# psoc6_04 register map
Vendor: Infineon Technologies; Series: PSOC6_04; File version: 1.0
CPU: CM4 r0p1, little endian, MPU, FPU, VTOR, 3 interrupt priority bits
Registers are 32-bit, read-write, reset 0x0 unless marked. A register's access mark holds for its fields unless they carry their own. Offsets are from the block's base; [hi:lo] are bit positions; {n}, {i} and the like mark numbered series; 'fields as' and 'values as' point back to an identical list; <NAME> marks a mode.

## SAR0 — SAR ADC with Sequencer
Base 0x409B0000
Same registers: SAR1 0x409C0000
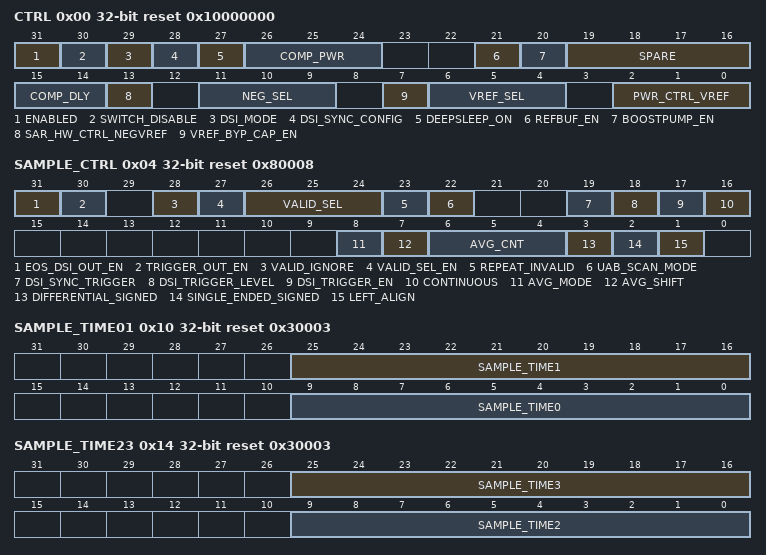
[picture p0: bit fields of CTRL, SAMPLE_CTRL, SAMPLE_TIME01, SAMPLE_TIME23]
0x00 CTRL reset 0x10000000 — Analog control register.
  [31] ENABLED — - 0: SAR disabled (put analog in power down and stop clocks), also can clear FW_TRIGGER on write. - 1: SAR IP enabled.
  [30] SWITCH_DISABLE — Disable SAR sequencer from enabling routing switches - 0: Normal mode, SAR sequencer changes switches according to pin address in channel configurations - 1: Switches disabled, SAR sequencer does not enable any switches. Other methods such as firmware control can be used to set the switches to route the signal to be converted through the SARMUX
  [29] DSI_MODE — SAR sequencer takes configuration from DSI signals (note this also has the same effect as SWITCH_DISABLE==1) - 0: Normal mode, SAR sequencer operates according to CHAN_EN enables and CHAN_CONFIG channel configurations - 1: CHAN_EN and channel configurations in CHAN_CONFIG are ignored
  [28] DSI_SYNC_CONFIG
  [27] DEEPSLEEP_ON — - 0: SARMUX disabled during System Deep Sleep power mode - 1: SARMUX remains enabled during System Deep Sleep power mode (if ENABLED=1)
  [26:24] COMP_PWR — Comparator power mode.
    0=P100 (Power = 100 percent, Use this for SAR Clock Frequency greater than 18MHz); 1=P80 (N/A); 2=P60 (Power = 60 percent, Use this for SAR Clock Frequency greater than 1.8MHz up to 18MHz.); 3=P50 (N/A); 4=P40 (N/A); 5=P30 (N/A); 6=P20 (Power = 20 percent, Use this for SAR Clock Frequency less than or equal to 1.8MHz); 7=P10 (N/A)
  [21] REFBUF_EN
  [20] BOOSTPUMP_EN
  [19:16] SPARE
  [15:14] COMP_DLY
    0=D2P5 (2.5ns delay, use this for 2.5Msps); 1=D4 (4.0ns delay, use this for 2.0Msps); 2=D10 (10ns delay, use this for 1.5Msps); 3=D12 (12ns delay, use this for 1.0Msps or less)
  [13] SAR_HW_CTRL_NEGVREF
  [11:9] NEG_SEL
    0=VSSA_KELVIN (NEG input of SARADC is connected to 'vssa_kelvin', gives more precision around zero. Note this opens both SARADC internal switches, therefore use this value to insert a break-before-make cycle on those switches when SWITCH_DISABLE is high.); 1=ART_VSSA (NEG input of SARADC is connected to VSSA in AROUTE close to the SARADC); 2=P1 (NEG input of SARADC is connected to P1 pin of SARMUX); 3=P3 (NEG input of SARADC is connected to P3 pin of SARMUX); 4=P5 (NEG input of SARADC is connected to P5 pin of SARMUX); 5=P7 (NEG input of SARADC is connected to P7 pin of SARMUX); 6=ACORE (NEG input of SARADC is connected to an ACORE in AROUTE); 7=VREF (NEG input of SARADC is shorted with VREF input of SARADC.)
  [7] VREF_BYP_CAP_EN — VREF bypass cap enable when VREF buffer is on
  [6:4] VREF_SEL
    0=VREF0 (VREF0 from PRB (VREF buffer on)); 1=VREF1 (VREF1 from PRB (VREF buffer on)); 2=VREF2 (VREF2 from PRB (VREF buffer on)); 3=VREF_AROUTE (VREF from AROUTE (VREF buffer on)); 4=VBGR (1.024V from BandGap (VREF buffer on)); 5=VREF_EXT (External precision Vref direct from a pin (low impedance path).); 6=VDDA_DIV_2 (Vdda/2 (VREF buffer on)); 7=VDDA
  [2:0] PWR_CTRL_VREF — VREF buffer low power mode.
    0=PWR_100 (full power (100 percent) (default), bypass cap, max clk_sar is 18MHz.); 1=PWR_80 (80 percent power); 2=PWR_60 (60 percent power); 3=PWR_50 (50 percent power); 4=PWR_40 (40 percent power); 5=PWR_30 (30 percent power); 6=PWR_20 (20 percent power); 7=PWR_10 (10 percent power)
0x04 SAMPLE_CTRL reset 0x80008 — Sample control register.
  [31] EOS_DSI_OUT_EN — Enable to output EOS_INTR. When enabled each time EOS_INTR is set by the hardware also a trigger pulse is send on the tr_sar_out signal.
  [30] TRIGGER_OUT_EN
  [28] VALID_IGNORE
  [27] VALID_SEL_EN
  [26:24] VALID_SEL
  [23] REPEAT_INVALID
  [22] UAB_SCAN_MODE
    0=UNSCHEDULED (Unscheduled UABs: one or more of the UABs scanned by the SAR is not scheduled, for each channel that scans a UAB the SAR will wait for a positive edge on the trigger output of that UAB. Caveat: in this mode the length of SAR scan can be variable.); 1=SCHEDULED (Scheduled UABs: All UABs scanned by the SAR are assumed to be properly scheduled, i.e. their output is assumed to be valid when sampled by the SAR and the SAR does not wait. In this mode the length of the SAR scan is constant. This mode requires that the SAR scans strictly periodically, i.e. the SAR has to either run continuously or has to be triggered by a periodic hardware trigger (TCPWM or UDB timer). It also requires that the end of the UAB valid phase is precisely aligned with the end of the SAR sample period (using UAB.STARTUP_DELAY). Normally this scheduling is done by Creator.)
  [19] DSI_SYNC_TRIGGER
  [18] DSI_TRIGGER_LEVEL
  [17] DSI_TRIGGER_EN — - 0: firmware trigger only: disable hardware trigger tr_sar_in. - 1: enable hardware trigger tr_sar_in (e.g. from TCPWM, GPIO etc)
  [16] CONTINUOUS
  [8] AVG_MODE — Averaging mode
    0=ACCUNDUMP (Accumulate and Dump (1st order accumulate and dump filter): a channel will be sampled back to back and averaged); 1=INTERLEAVED (Interleaved: Each scan (trigger) one sample is taken per channel and averaged over several scans. Interleaved averaging cannot be set by SAR_CLOCK_SEL.CLOCK_SEL =1.)
  [7] AVG_SHIFT
  [6:4] AVG_CNT
  [3] DIFFERENTIAL_SIGNED
    0=UNSIGNED (result data is unsigned (zero extended if needed)); 1=SIGNED (Default: result data is signed (sign extended if needed))
  [2] SINGLE_ENDED_SIGNED
    0=UNSIGNED (Default: result data is unsigned (zero extended if needed)); 1=SIGNED (result data is signed (sign extended if needed))
  [1] LEFT_ALIGN
0x10 SAMPLE_TIME01 reset 0x30003 — Sample time specification ST0 and ST1
  [25:16] SAMPLE_TIME1
  [9:0] SAMPLE_TIME0 — Sample time0 (aperture) in ADC clock cycles. Note that actual sample time is one clock less than specified here. The minimum sample time is 167ns, which is 3.0 cycles (4 in this field) with an 18MHz clock. Minimum legal value in this register is 2.
0x14 SAMPLE_TIME23 reset 0x30003 — Sample time specification ST2 and ST3
  [25:16] SAMPLE_TIME3, [9:0] SAMPLE_TIME2
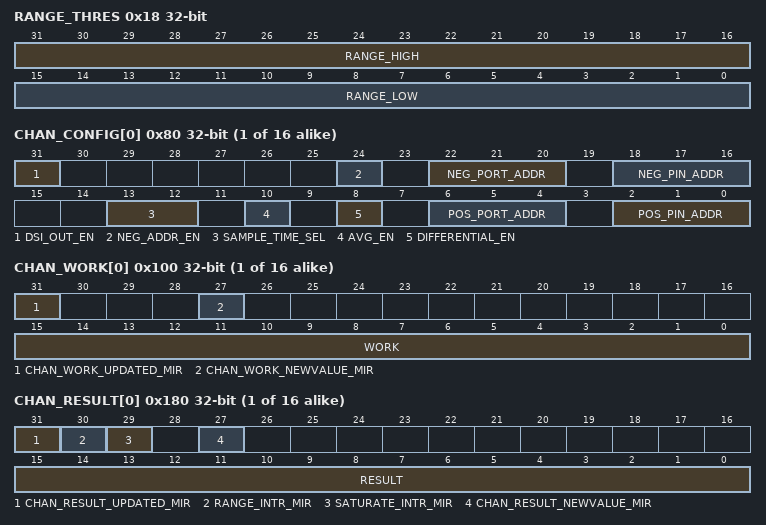
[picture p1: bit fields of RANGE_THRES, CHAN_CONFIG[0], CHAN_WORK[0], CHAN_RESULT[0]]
0x18 RANGE_THRES — Global range detect threshold register.
  [31:16] RANGE_HIGH — High threshold for range detect.
  [15:0] RANGE_LOW — Low threshold for range detect.
0x1C RANGE_COND — Global range detect mode register.
  [31:30] RANGE_COND — Range condition select.
    0=BELOW (result < RANGE_LOW); 1=INSIDE (RANGE_LOW <= result < RANGE_HIGH); 2=ABOVE (RANGE_HIGH <= result); 3=OUTSIDE (result < RANGE_LOW || RANGE_HIGH <= result)
0x20 CHAN_EN — Enable bits for the channels
  [15:0] CHAN_EN — Channel enable. - 0: the corresponding channel is disabled. - 1: the corresponding channel is enabled, it will be included in the next scan.
0x24 START_CTRL — Start control register (firmware trigger).
  [0] FW_TRIGGER — When firmware writes a 1 here it will trigger the next scan of enabled channels, hardware clears this bit when the scan started with this trigger is completed. If scanning continuously the trigger is ignored and hardware clears this bit after the next scan is done. This bit is also cleared when the SAR is disabled. This field cannot be set when SAR_CLOCK_SEL.CLOCK_SEL =1.
{0x80+4i} CHAN_CONFIG[{i}] (i=0..15) — Channel configuration register.
  [31] DSI_OUT_EN
  [24] NEG_ADDR_EN
  [22:20] NEG_PORT_ADDR
    0=SARMUX (SARMUX pins.); 5=AROUTE_VIRT2 (AROUTE virtual port2 (VPORT2)); 6=AROUTE_VIRT1 (AROUTE virtual port1 (VPORT1)); 7=SARMUX_VIRT (SARMUX virtual port (VPORT0))
  [18:16] NEG_PIN_ADDR — Address of the neg pin to be sampled by this channel. When NEG_PORT_ADDR = SARMUX, NEG_PIN_ADDR selects the pin of the SARMUX port.
  [13:12] SAMPLE_TIME_SEL
  [10] AVG_EN
  [8] DIFFERENTIAL_EN
  [6:4] POS_PORT_ADDR
    0=SARMUX (SARMUX pins.); {v}=CTB{v-1} (v=1..4); 5=AROUTE_VIRT2 (AROUTE virtual port2 (VPORT2)); 6=AROUTE_VIRT1 (AROUTE virtual port1 (VPORT1)); 7=SARMUX_VIRT (SARMUX virtual port (VPORT0))
  [2:0] POS_PIN_ADDR — Address of the pin to be sampled by this channel (connected to Vplus). When POS_PORT_ADDR = SARMUX, POS_PIN_ADDR selects the pin of the SARMUX port. When POS_PORT_ADDR is set to one of the CTBs, POS_PIN_ADDR selects particular opamp output. When POS_PORT_ADDR is set to VPORT0, POS_PIN_ADDR = 0, selects temperature sensor output, POS_PIN_ADDR = 1 selects AMUXBUS-A and POS_PIN_ADDR = 2 selects AMUXBUS-B.
{0x100+4i} CHAN_WORK[{i}] (i=0..15) ro (reset mask 0x88000000) — Channel working data register
  [31] CHAN_WORK_UPDATED_MIR — mirror bit of corresponding bit in SAR_CHAN_WORK_UPDATED register. This field cannot be read if SAR_CLOCK_SEL.CLOCK_SEL =1.
  [27] CHAN_WORK_NEWVALUE_MIR — mirror bit of corresponding bit in SAR_CHAN_WORK_NEWVALUE register. This field cannot be read if SAR_CLOCK_SEL.CLOCK_SEL =1.
  [15:0] WORK — SAR conversion working data of the channel. The data is written here right after sampling this channel. This field cannot be read if SAR_CLOCK_SEL.CLOCK_SEL =1.
{0x180+4i} CHAN_RESULT[{i}] (i=0..15) ro (reset mask 0xE8000000) — Channel result data register
  [31] CHAN_RESULT_UPDATED_MIR — mirror bit of corresponding bit in SAR_CHAN_RESULT_UPDATED register. This field cannot be read if SAR_CLOCK_SEL.CLOCK_SEL =1.
  [30] RANGE_INTR_MIR — mirror bit of corresponding bit in SAR_RANGE_INTR register. This field cannot be read if SAR_CLOCK_SEL.CLOCK_SEL =1.
  [29] SATURATE_INTR_MIR — mirror bit of corresponding bit in SAR_SATURATE_INTR register. This field cannot be read if SAR_CLOCK_SEL.CLOCK_SEL =1.
  [27] CHAN_RESULT_NEWVALUE_MIR — mirror bit of corresponding bit in SAR_CHAN_RESULT_NEWVALUE register. This field cannot be read if SAR_CLOCK_SEL.CLOCK_SEL =1.
  [15:0] RESULT — SAR conversion result of the channel. The data is copied here from the WORK field after all enabled channels in this scan have been sampled. This field cannot be read if SAR_CLOCK_SEL.CLOCK_SEL =1.
0x200 CHAN_WORK_UPDATED ro — Channel working data register 'updated' bits
  [15:0] CHAN_WORK_UPDATED — If set the corresponding WORK register was updated, i.e. was already sampled during the current scan and, in case of Interleaved averaging, reached the averaging count. If this bit is low then either the channel is not enabled or the averaging count is not yet reached for Interleaved averaging. This field cannot be read if SAR_CLOCK_SEL.CLOCK_SEL =1.
0x204 CHAN_RESULT_UPDATED ro — Channel result data register 'updated' bits
  [15:0] CHAN_RESULT_UPDATED — If set the corresponding RESULT register was updated, i.e. was sampled during the previous scan and, in case of Interleaved averaging, reached the averaging count. If this bit is low then either the channel is not enabled or the averaging count is not yet reached for Interleaved averaging. This field cannot be read if SAR_CLOCK_SEL.CLOCK_SEL =1.
0x208 CHAN_WORK_NEWVALUE ro — Channel working data register 'new value' bits
  [15:0] CHAN_WORK_NEWVALUE — If set the corresponding WORK data received a new value, i.e. was already sampled during the current scan and data was valid. In case of a UAB this New Value bit reflects the value of UAB.valid output, for anything else the data is always valid. In case of averaging this New Value bit is an OR of all the valid bits received by each conversion. This field cannot be read if SAR_CLOCK_SEL.CLOCK_SEL =1.
0x20C CHAN_RESULT_NEWVALUE ro — Channel result data register 'new value' bits
  [15:0] CHAN_RESULT_NEWVALUE — If set the corresponding RESULT data received a new value, i.e. was sampled during the last scan and data was valid. In case of a UAB this New Value bit reflects the value of UAB.valid output, for anything else the data is always valid. In case of averaging this New Value bit is an OR of all the valid bits received by each conversion. This field cannot be read if SAR_CLOCK_SEL.CLOCK_SEL =1.
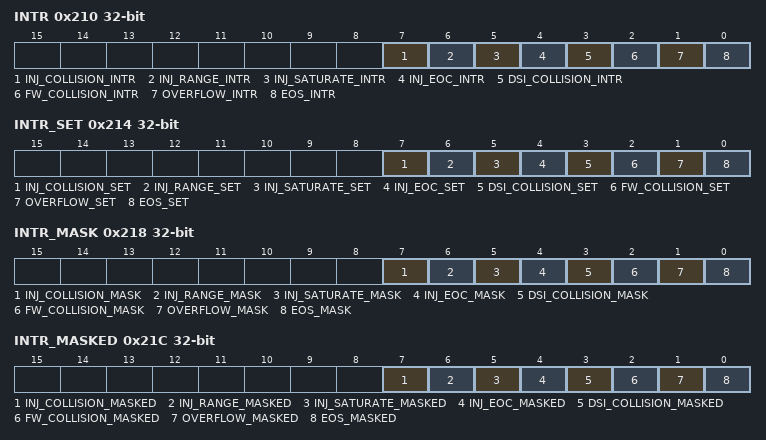
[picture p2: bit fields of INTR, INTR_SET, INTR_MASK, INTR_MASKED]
0x210 INTR — Interrupt request register.
  [7] INJ_COLLISION_INTR
  [6] INJ_RANGE_INTR
  [5] INJ_SATURATE_INTR
  [4] INJ_EOC_INTR
  [3] DSI_COLLISION_INTR — This interrupt is set when a hardware trigger signal is asserted while the SAR is BUSY. Raising this interrupt is delayed to when the scan caused by the hardware trigger has been completed, i.e. not when the preceding scan with which this trigger collided is completed. When this interrupt is set it implies that the channels were sampled later than was intended (jitter). Write with '1' to clear bit.
  [2] FW_COLLISION_INTR
  [1] OVERFLOW_INTR
  [0] EOS_INTR
0x214 INTR_SET — Interrupt set request register
  [7] INJ_COLLISION_SET, [6] INJ_RANGE_SET, [5] INJ_SATURATE_SET, [4] INJ_EOC_SET, [3] DSI_COLLISION_SET, [2] FW_COLLISION_SET, [1] OVERFLOW_SET, [0] EOS_SET
0x218 INTR_MASK — Interrupt mask register.
  [7] INJ_COLLISION_MASK, [6] INJ_RANGE_MASK, [5] INJ_SATURATE_MASK, [4] INJ_EOC_MASK, [3] DSI_COLLISION_MASK, [2] FW_COLLISION_MASK, [1] OVERFLOW_MASK, [0] EOS_MASK
0x21C INTR_MASKED ro — Interrupt masked request register
  [7] INJ_COLLISION_MASKED, [6] INJ_RANGE_MASKED, [5] INJ_SATURATE_MASKED, [4] INJ_EOC_MASKED, [3] DSI_COLLISION_MASKED, [2] FW_COLLISION_MASKED, [1] OVERFLOW_MASKED, [0] EOS_MASKED
0x220 SATURATE_INTR — Saturate interrupt request register.
  [15:0] SATURATE_INTR — Saturate Interrupt: hardware sets this interrupt for each channel if a conversion result (before averaging) of that channel is either 0x000 or 0xFFF, this is an indication that the ADC likely saturated. Write with '1' to clear bit.
0x224 SATURATE_INTR_SET — Saturate interrupt set request register
  [15:0] SATURATE_SET — Write with '1' to set corresponding bit in interrupt request register.
0x228 SATURATE_INTR_MASK — Saturate interrupt mask register.
  [15:0] SATURATE_MASK — Mask bit for corresponding bit in interrupt request register.
0x22C SATURATE_INTR_MASKED ro — Saturate interrupt masked request register
  [15:0] SATURATE_MASKED — Logical and of corresponding request and mask bits.
0x230 RANGE_INTR — Range detect interrupt request register.
  [15:0] RANGE_INTR — Range detect Interrupt: hardware sets this interrupt for each channel if the conversion result (after averaging) of that channel met the condition specified by the SAR_RANGE registers. Write with '1' to clear bit.
0x234 RANGE_INTR_SET — Range detect interrupt set request register
  [15:0] RANGE_SET — Write with '1' to set corresponding bit in interrupt request register.
0x238 RANGE_INTR_MASK — Range detect interrupt mask register.
  [15:0] RANGE_MASK — Mask bit for corresponding bit in interrupt request register.
0x23C RANGE_INTR_MASKED ro — Range interrupt masked request register
  [15:0] RANGE_MASKED — Logical and of corresponding request and mask bits.
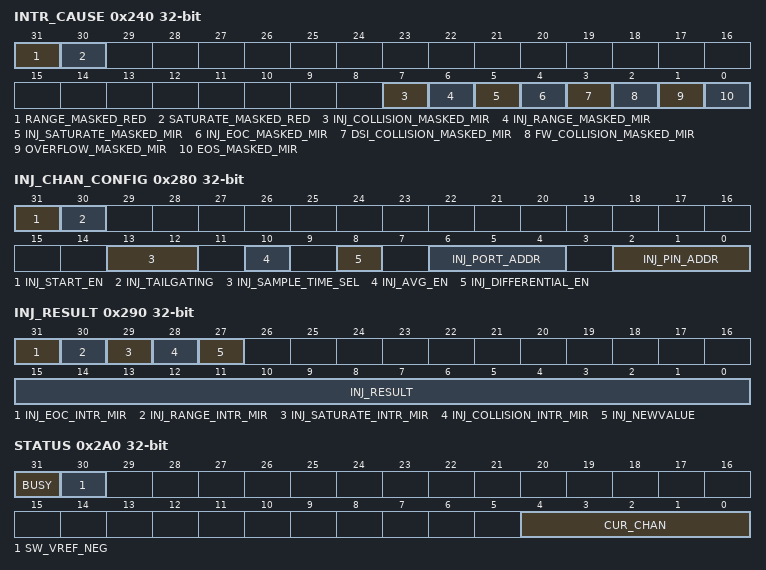
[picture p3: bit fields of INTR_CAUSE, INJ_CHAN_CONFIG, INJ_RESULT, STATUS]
0x240 INTR_CAUSE ro — Interrupt cause register
  [31] RANGE_MASKED_RED, [30] SATURATE_MASKED_RED, [7] INJ_COLLISION_MASKED_MIR, [6] INJ_RANGE_MASKED_MIR, [5] INJ_SATURATE_MASKED_MIR, [4] INJ_EOC_MASKED_MIR, [3] DSI_COLLISION_MASKED_MIR, [2] FW_COLLISION_MASKED_MIR, [1] OVERFLOW_MASKED_MIR, [0] EOS_MASKED_MIR
0x280 INJ_CHAN_CONFIG — Injection channel configuration register.
  [31] INJ_START_EN
  [30] INJ_TAILGATING
  [13:12] INJ_SAMPLE_TIME_SEL
  [10] INJ_AVG_EN
  [8] INJ_DIFFERENTIAL_EN
  [6:4] INJ_PORT_ADDR
    0=SARMUX (SARMUX pins.); {v}=CTB{v-1} (v=1..4); 6=AROUTE_VIRT (AROUTE virtual port); 7=SARMUX_VIRT (SARMUX virtual port)
  [2:0] INJ_PIN_ADDR
0x290 INJ_RESULT ro (reset mask 0xF8000000) — Injection channel result register
  [31] INJ_EOC_INTR_MIR — mirror bit of corresponding bit in SAR_INTR register. This field cannot be read if SAR_CLOCK_SEL.CLOCK_SEL =1.
  [30] INJ_RANGE_INTR_MIR — mirror bit of corresponding bit in SAR_INTR register. This field cannot be read if SAR_CLOCK_SEL.CLOCK_SEL =1.
  [29] INJ_SATURATE_INTR_MIR — mirror bit of corresponding bit in SAR_INTR register. This field cannot be read if SAR_CLOCK_SEL.CLOCK_SEL =1.
  [28] INJ_COLLISION_INTR_MIR — mirror bit of corresponding bit in SAR_INTR register. This field cannot be read if SAR_CLOCK_SEL.CLOCK_SEL =1.
  [27] INJ_NEWVALUE — The data in this register received a new value (only relevant for UAB, this bit shows the value of the UAB valid bit). This field cannot be read if SAR_CLOCK_SEL.CLOCK_SEL =1.
  [15:0] INJ_RESULT — SAR conversion result of the channel. This field cannot be read if SAR_CLOCK_SEL.CLOCK_SEL =1.
0x2A0 STATUS ro — Current status of internal SAR registers (mostly for debug)
  [31] BUSY — If high then the SAR is busy with a conversion. This bit is always high when CONTINUOUS is set. Firmware should wait for this bit to be low before putting the SAR in power down.
  [30] SW_VREF_NEG — the current switch status, including DSI and sequencer controls, of the switch in the SARADC that shorts NEG with VREF input (see NEG_SEL). This field cannot be read if SAR_CLOCK_SEL.CLOCK_SEL =1.
  [4:0] CUR_CHAN — current channel being sampled (channel 16 indicates the injection channel), only valid if BUSY. This field cannot be read if SAR_CLOCK_SEL.CLOCK_SEL =1.
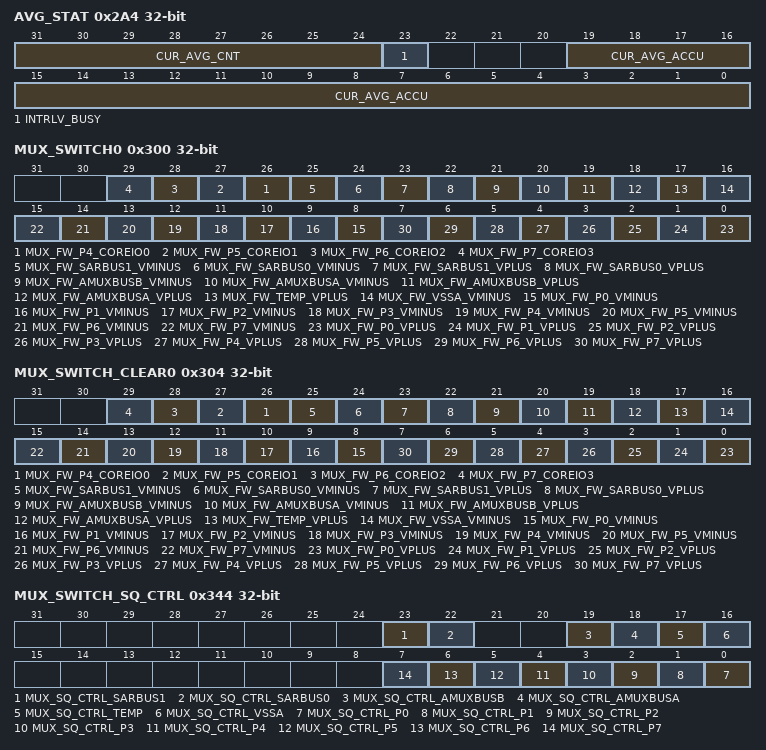
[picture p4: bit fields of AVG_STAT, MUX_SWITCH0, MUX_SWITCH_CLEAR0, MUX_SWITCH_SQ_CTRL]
0x2A4 AVG_STAT ro — Current averaging status (for debug)
  [31:24] CUR_AVG_CNT — the current value of the averaging counter. Note that the value shown is updated after the sampling time and therefore runs ahead of the accumulator update. This field cannot be read if SAR_CLOCK_SEL.CLOCK_SEL =1.
  [23] INTRLV_BUSY — If high then the SAR is in the middle of Interleaved averaging spanning several scans. While this bit is high the Firmware should not make any changes to the configuration registers otherwise some results may be incorrect. Note that the CUR_AVG_CNT status register below gives an indication how many more scans need to be done to complete the Interleaved averaging. This bit can be cleared by changing the averaging mode to ACCUNDUMP or by disabling the SAR.
  [19:0] CUR_AVG_ACCU — the current value of the averaging accumulator. This field cannot be read if SAR_CLOCK_SEL.CLOCK_SEL =1.
0x300 MUX_SWITCH0 — SARMUX Firmware switch controls
  [n+22] MUX_FW_P{n}_COREIO{n-4} (n=4..7), [25] MUX_FW_SARBUS1_VMINUS, [24] MUX_FW_SARBUS0_VMINUS, [23] MUX_FW_SARBUS1_VPLUS, [22] MUX_FW_SARBUS0_VPLUS, [21] MUX_FW_AMUXBUSB_VMINUS, [20] MUX_FW_AMUXBUSA_VMINUS, [19] MUX_FW_AMUXBUSB_VPLUS, [18] MUX_FW_AMUXBUSA_VPLUS, [17] MUX_FW_TEMP_VPLUS, [16] MUX_FW_VSSA_VMINUS, [n+8] MUX_FW_P{n}_VMINUS (n=0..7), [n] MUX_FW_P{n}_VPLUS (n=0..7)
0x304 MUX_SWITCH_CLEAR0 — SARMUX Firmware switch control clear
  fields as MUX_SWITCH0
0x344 MUX_SWITCH_SQ_CTRL — SARMUX switch Sar Sequencer control
  [23] MUX_SQ_CTRL_SARBUS1 — for sarbus1 switch
  [22] MUX_SQ_CTRL_SARBUS0 — for sarbus0 switch
  [19] MUX_SQ_CTRL_AMUXBUSB — for amuxbusb switches
  [18] MUX_SQ_CTRL_AMUXBUSA — for amuxbusa switch
  [17] MUX_SQ_CTRL_TEMP — for temp switch
  [16] MUX_SQ_CTRL_VSSA — for vssa switch
  [n] MUX_SQ_CTRL_P{n} (n=0..7) — for P{n} switches
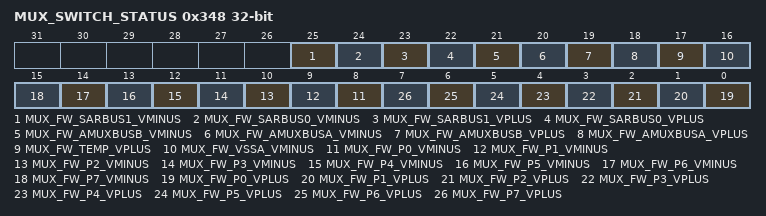
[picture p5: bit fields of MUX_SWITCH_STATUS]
0x348 MUX_SWITCH_STATUS ro — SARMUX switch status
  [25] MUX_FW_SARBUS1_VMINUS — switch status of corresponding bit in MUX_SWITCH0. This field cannot be read if SAR_CLOCK_SEL.CLOCK_SEL =1.
  [24] MUX_FW_SARBUS0_VMINUS — switch status of corresponding bit in MUX_SWITCH0. This field cannot be read if SAR_CLOCK_SEL.CLOCK_SEL =1.
  [23] MUX_FW_SARBUS1_VPLUS — switch status of corresponding bit in MUX_SWITCH0. This field cannot be read if SAR_CLOCK_SEL.CLOCK_SEL =1.
  [22] MUX_FW_SARBUS0_VPLUS — switch status of corresponding bit in MUX_SWITCH0. This field cannot be read if SAR_CLOCK_SEL.CLOCK_SEL =1.
  [21] MUX_FW_AMUXBUSB_VMINUS — switch status of corresponding bit in MUX_SWITCH0. This field cannot be read if SAR_CLOCK_SEL.CLOCK_SEL =1.
  [20] MUX_FW_AMUXBUSA_VMINUS — switch status of corresponding bit in MUX_SWITCH0. This field cannot be read if SAR_CLOCK_SEL.CLOCK_SEL =1.
  [19] MUX_FW_AMUXBUSB_VPLUS — switch status of corresponding bit in MUX_SWITCH0. This field cannot be read if SAR_CLOCK_SEL.CLOCK_SEL =1.
  [18] MUX_FW_AMUXBUSA_VPLUS — switch status of corresponding bit in MUX_SWITCH0. This field cannot be read if SAR_CLOCK_SEL.CLOCK_SEL =1.
  [17] MUX_FW_TEMP_VPLUS — switch status of corresponding bit in MUX_SWITCH0. This field cannot be read if SAR_CLOCK_SEL.CLOCK_SEL =1.
  [16] MUX_FW_VSSA_VMINUS — switch status of corresponding bit in MUX_SWITCH0. This field cannot be read if SAR_CLOCK_SEL.CLOCK_SEL =1.
  [n+8] MUX_FW_P{n}_VMINUS (n=0..7) — switch status of corresponding bit in MUX_SWITCH0. This field cannot be read if SAR_CLOCK_SEL.CLOCK_SEL =1.
  [n] MUX_FW_P{n}_VPLUS (n=0..7) — switch status of corresponding bit in MUX_SWITCH0. This field cannot be read if SAR_CLOCK_SEL.CLOCK_SEL =1.
